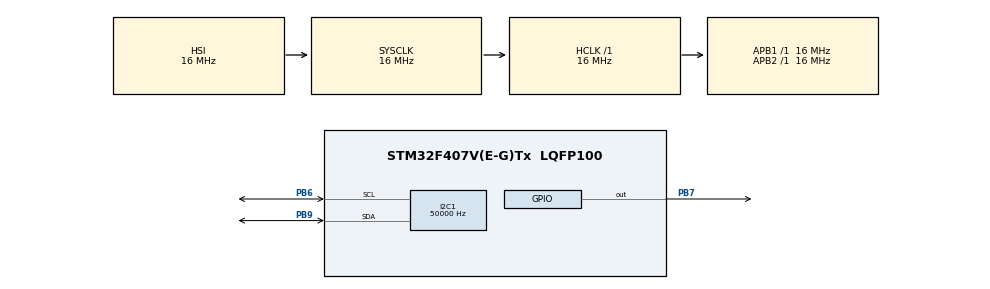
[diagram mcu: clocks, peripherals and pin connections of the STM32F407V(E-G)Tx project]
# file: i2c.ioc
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I2C1.ClockSpeed=50000
Mcu.Family=STM32F4
Mcu.Name=STM32F407V(E-G)Tx
Mcu.Package=LQFP100
NVIC.PriorityGroup=NVIC_PRIORITYGROUP_4
PB6.Mode=I2C
PB6.Signal=I2C1_SCL
PB7.Signal=GPIO_Output
PB9.Mode=I2C
PB9.Signal=I2C1_SDA
ProjectManager.HeapSize=0x200
ProjectManager.StackSize=0x400
ProjectManager.TargetToolchain=SW4STM32
RCC.AHBFreq_Value=16000000
RCC.APB1Freq_Value=16000000
RCC.APB2Freq_Value=16000000
RCC.CortexFreq_Value=16000000
RCC.HSE_VALUE=25000000
RCC.HSI_VALUE=16000000
RCC.LSE_VALUE=32768
RCC.SYSCLKFreq_VALUE=16000000
RCC.VCOOutputFreq_Value=192000000
board=custom

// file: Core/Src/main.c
/* USER CODE BEGIN Header */
/**
  ******************************************************************************
  * @file           : main.c
  * @brief          : Main program body
  ******************************************************************************
  * @attention
  *
  * <h2><center>&copy; Copyright (c) 2021 STMicroelectronics.
  * All rights reserved.</center></h2>
  *
  * This software component is licensed by ST under BSD 3-Clause license,
  * the "License"; You may not use this file except in compliance with the
  * License. You may obtain a copy of the License at:
  *                        opensource.org/licenses/BSD-3-Clause
  *
  ******************************************************************************
  */
/* USER CODE END Header */
#include <pca9685.h>
#include "main.h"

I2C_HandleTypeDef hi2c1;

void SystemClock_Config(void);
static void MX_GPIO_Init(void);
static void MX_I2C1_Init(void);

/* USER CODE BEGIN 0 */
void i2c_write(uint8_t DevAddress,uint8_t *pData, uint16_t num)
{
	HAL_I2C_Master_Transmit(&hi2c1,DevAddress,pData,num,1000);
}
void OEn_pin(uint8_t value)
{
	HAL_GPIO_WritePin(GPIOB,GPIO_PIN_7,value);
}
/* USER CODE END 0 */

int main(void)
{

  /* MCU Configuration--------------------------------------------------------*/

  /* Reset of all peripherals, Initializes the Flash interface and the Systick. */
  HAL_Init();

  /* Configure the system clock */
  SystemClock_Config();

  /* Initialize all configured peripherals */
  MX_GPIO_Init();
  MX_I2C1_Init();

  /* Infinite loop */
  /* USER CODE BEGIN WHILE */
 PCA9685_dev dev;
 HAL_Delay(10);
 dev.i2c_write = i2c_write;
 dev.OEn_pin = OEn_pin;
 PCA9685_Init(&dev,0x00, AUTO_INC|START, TOTEM);
 HAL_Delay(100);
 PCA9685_SET_AllLed(&dev, 0x0199, 0x0FCC);
 //PCA9685_SET_Led(&dev,  LED0, 0x0199, 0x04CC);
 //PCA9685_OUT_SleepMode(&dev);
 //PCA9685_SET_SleepMode(&dev);
 while (1)
  {
    /* USER CODE END WHILE */

  }
}

void SystemClock_Config(void)
{
  RCC_OscInitTypeDef RCC_OscInitStruct = {0};
  RCC_ClkInitTypeDef RCC_ClkInitStruct = {0};

  /** Configure the main internal regulator output voltage
  */
  __HAL_RCC_PWR_CLK_ENABLE();
  __HAL_PWR_VOLTAGESCALING_CONFIG(PWR_REGULATOR_VOLTAGE_SCALE1);
  /** Initializes the RCC Oscillators according to the specified parameters
  * in the RCC_OscInitTypeDef structure.
  */
  RCC_OscInitStruct.OscillatorType = RCC_OSCILLATORTYPE_HSI;
  RCC_OscInitStruct.HSIState = RCC_HSI_ON;
  RCC_OscInitStruct.HSICalibrationValue = RCC_HSICALIBRATION_DEFAULT;
  RCC_OscInitStruct.PLL.PLLState = RCC_PLL_NONE;
  if (HAL_RCC_OscConfig(&RCC_OscInitStruct) != HAL_OK)
  {
    Error_Handler();
  }
  /** Initializes the CPU, AHB and APB buses clocks
  */
  RCC_ClkInitStruct.ClockType = RCC_CLOCKTYPE_HCLK|RCC_CLOCKTYPE_SYSCLK
                              |RCC_CLOCKTYPE_PCLK1|RCC_CLOCKTYPE_PCLK2;
  RCC_ClkInitStruct.SYSCLKSource = RCC_SYSCLKSOURCE_HSI;
  RCC_ClkInitStruct.AHBCLKDivider = RCC_SYSCLK_DIV1;
  RCC_ClkInitStruct.APB1CLKDivider = RCC_HCLK_DIV1;
  RCC_ClkInitStruct.APB2CLKDivider = RCC_HCLK_DIV1;

  if (HAL_RCC_ClockConfig(&RCC_ClkInitStruct, FLASH_LATENCY_0) != HAL_OK)
  {
    Error_Handler();
  }
}

static void MX_I2C1_Init(void)
{

  hi2c1.Instance = I2C1;
  hi2c1.Init.ClockSpeed = 50000;
  hi2c1.Init.DutyCycle = I2C_DUTYCYCLE_2;
  hi2c1.Init.OwnAddress1 = 0;
  hi2c1.Init.AddressingMode = I2C_ADDRESSINGMODE_7BIT;
  hi2c1.Init.DualAddressMode = I2C_DUALADDRESS_DISABLE;
  hi2c1.Init.OwnAddress2 = 0;
  hi2c1.Init.GeneralCallMode = I2C_GENERALCALL_DISABLE;
  hi2c1.Init.NoStretchMode = I2C_NOSTRETCH_DISABLE;
  if (HAL_I2C_Init(&hi2c1) != HAL_OK)
  {
    Error_Handler();
  }

}

static void MX_GPIO_Init(void)
{
  GPIO_InitTypeDef GPIO_InitStruct = {0};

  /* GPIO Ports Clock Enable */
  __HAL_RCC_GPIOB_CLK_ENABLE();

  /*Configure GPIO pin Output Level */
  HAL_GPIO_WritePin(GPIOB, GPIO_PIN_7, GPIO_PIN_RESET);

  /*Configure GPIO pin : PB7 */
  GPIO_InitStruct.Pin = GPIO_PIN_7;
  GPIO_InitStruct.Mode = GPIO_MODE_OUTPUT_PP;
  GPIO_InitStruct.Pull = GPIO_NOPULL;
  GPIO_InitStruct.Speed = GPIO_SPEED_FREQ_LOW;
  HAL_GPIO_Init(GPIOB, &GPIO_InitStruct);

}

void Error_Handler(void)
{
}

/************************ (C) COPYRIGHT STMicroelectronics *****END OF FILE****/
